# nrf54h20_enga_sysctrl register map
Vendor: Nordic Semiconductor; Series: nRF54h; File version: 1
Registers are 32-bit, read-write, reset 0x0 unless marked. A register's access mark holds for its fields unless they carry their own. Offsets are from the block's base; [hi:lo] are bit positions; lines under a group give offsets from that group; {n}, {i} and the like mark numbered series; 'fields as' and 'values as' point back to an identical list.

## LFRC_S — LFRC peripheral
Base 0x5F951000
0x00 TASKS_CAL wo — Start the calibration of RC oscillator
  [0] TASKS_CAL
    1=Trigger task
0x04 TASKS_CANCELCAL wo — Cancel the calibration
  [0] TASKS_CANCELCAL
    1=Trigger task
0x100 EVENTS_CALDONE — Calibration done
  [0] EVENTS_CALDONE
    0=NotGenerated (Event not generated); 1=Generated (Event generated)
0x104 EVENTS_TRIMDONE — Trim done
  [0] EVENTS_TRIMDONE
    values as EVENTS_CALDONE.EVENTS_CALDONE
0x108 EVENTS_TRIMERROR — Trim error
  [0] EVENTS_TRIMERROR
    values as EVENTS_CALDONE.EVENTS_CALDONE
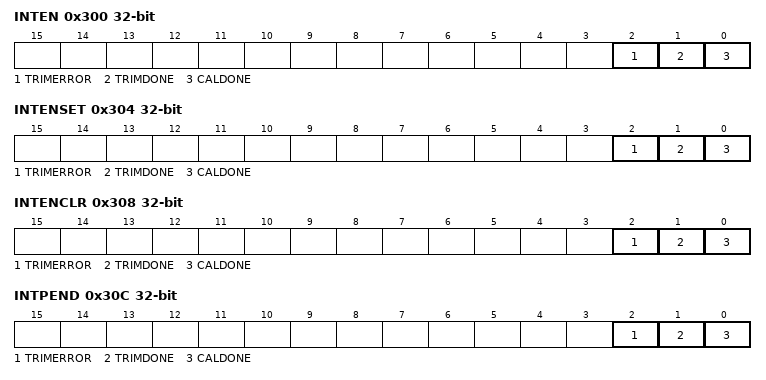
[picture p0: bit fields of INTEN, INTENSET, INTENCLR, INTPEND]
0x300 INTEN — Enable or disable interrupt
  [all] fields
    0=Disabled; 1=Enabled
  [2] TRIMERROR — Enable or disable interrupt for event TRIMERROR
  [1] TRIMDONE — Enable or disable interrupt for event TRIMDONE
  [0] CALDONE — Enable or disable interrupt for event CALDONE
0x304 INTENSET — Enable interrupt
  [all] fields
    on read: 0=Disabled (Read: Disabled); 1=Enabled (Read: Enabled) | on write: 1=Set (Enable)
  [2] TRIMERROR — Write '1' to enable interrupt for event TRIMERROR
  [1] TRIMDONE — Write '1' to enable interrupt for event TRIMDONE
  [0] CALDONE — Write '1' to enable interrupt for event CALDONE
0x308 INTENCLR — Disable interrupt
  [all] fields
    on read: 0=Disabled (Read: Disabled); 1=Enabled (Read: Enabled) | on write: 1=Clear (Disable)
  [2] TRIMERROR — Write '1' to disable interrupt for event TRIMERROR
  [1] TRIMDONE — Write '1' to disable interrupt for event TRIMDONE
  [0] CALDONE — Write '1' to disable interrupt for event CALDONE
0x30C INTPEND ro — Pending interrupts
  [all] fields
    on read: 0=NotPending (Read: Not pending); 1=Pending (Read: Pending)
  [2] TRIMERROR — Read pending status of interrupt for event TRIMERROR
  [1] TRIMDONE — Read pending status of interrupt for event TRIMDONE
  [0] CALDONE — Read pending status of interrupt for event CALDONE
0x400 STATUSTRIM ro reset 0xA — Current LFRCOSC trimming value.
  [5:0] VAL — TRIM value
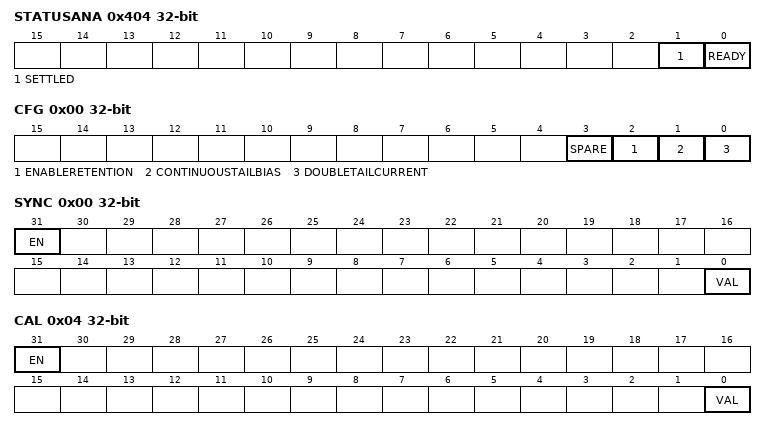
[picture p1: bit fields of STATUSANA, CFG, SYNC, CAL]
0x404 STATUSANA ro — Status of analog module output signals
  [1] SETTLED — Current value of the SETTLED signal from the analog module
  [0] READY — Current value of the READY signal from the analog module
0x410 CONFIG group — Unspecified
  0x00 CFG — Override the configuration
    [all] fields
      0=Disabled; 1=Enabled
    [3] SPARE — Deprecated field - Spare general purpose configuration bits. Register in NVM.
    [2] ENABLERETENTION — Deprecated field - Enable retention for CAL
    [1] CONTINUOUSTAILBIAS — Deprecated field - Enable continuous tail bias in comparator CMPX_INT, only for debugging purposes.
    [0] DOUBLETAILCURRENT — Deprecated field - Double tail current in comparator CMPX_INT, only for debugging purposes.
0x420 CAL group — Unspecified
  0x00 LENGTH reset 0x2 — Measurement cycle count length used while calibration
    [2:0] LENGTH — Number of cycles
      0=N64 (64 cycles); 1=N128 (128 cycles); 2=N256 (256 cycles); 3=N512 (512 cycles)
  0x04 TRIMLIMITLO — Lower trim limit
    [17:0] VALUE — TRIM limit value.
  0x08 TRIMLIMITHI reset 0x3FFFF — Higher trim limit
    [17:0] VALUE — TRIM limit value
  {0xC+4j} RESULT[{j}] (j=0..1) ro — Description collection: Calibration result from CAL=n
    [31:0] RESULT — The result in 16MHz clock cycles
  0x14 NHI ro — Number of cycles when the CAL signal is high
    [11:0] NHI — Number of cycles
  0x18 LFRCOSCTRIM reset 0xA — Initial coarse frequency trimming value for the oscillator.
    [5:0] VAL — TRIM value
0x480 MIRROR reset 0x1 — Enable LOCK for mirrored registers
  [0] LOCK — Lock for mirrored registers
    0=Disabled (Lock disabled); 1=Enabled (Lock enabled)
0x484 PWRUPCTRL — Power up control
  [1:0] CTRL
    0=Automatically handled by the peripheral; 1=PowerUp; 2=PowerDown
0x500 OVERRIDE group — Unspecified
  0x00 SYNC — Override the SYNC signal to the LFRC32K analog module
    [31] EN — Enable the override
      0=Disabled (Override is disabled); 1=Enabled (Override is enabled)
    [0] VAL — Override value for the signal
  0x04 CAL — Override the CAL signal to the LFRC32K analog module
    fields as OVERRIDE.SYNC
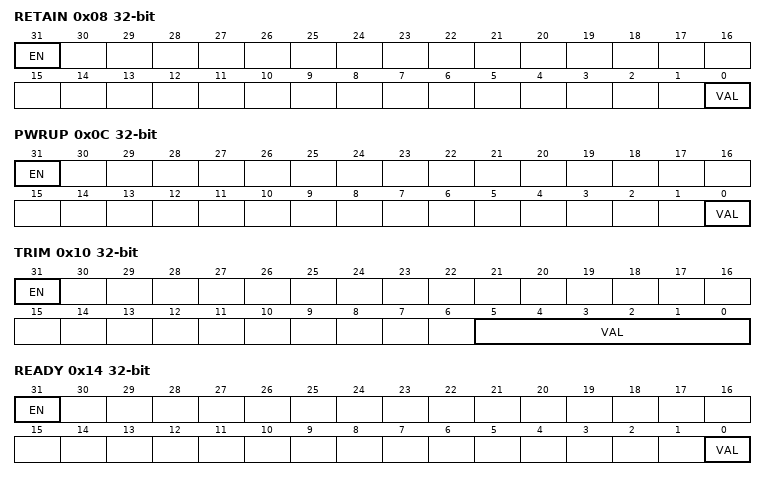
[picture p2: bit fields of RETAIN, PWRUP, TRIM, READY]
  0x08 RETAIN — Override the RETAIN signal to the LFRC32K analog module
    fields as OVERRIDE.SYNC
  0x0C PWRUP — Override the PWRUP signal to the LFRC32K analog module
    fields as OVERRIDE.SYNC
  0x10 TRIM — Override the TRIM[5:0] signal to the LFRC32K analog module
    [31] EN — Enable the override
      values as OVERRIDE.SYNC.EN
    [5:0] VAL — TRIM value
  0x14 READY — Override the READY signal from the analog module
    [31] EN — Enable the override
      values as OVERRIDE.SYNC.EN
    [0] VAL — Current value of the signal
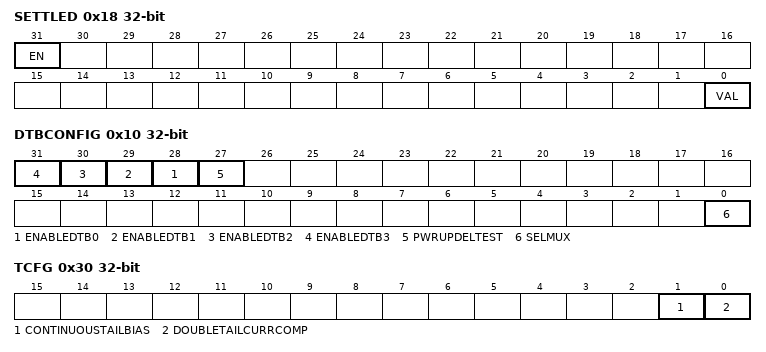
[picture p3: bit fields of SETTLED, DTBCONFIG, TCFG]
  0x18 SETTLED — Override the SETTLED signal from the analog module
    fields as OVERRIDE.READY
0x600 DFT group — Unspecified
  0x00 ATB0CONFIG — Analog Test Bus 0 (ATB0) configuration
    [31] EN — Enable the analog test bus
      0=Disabled (Analog test bus is disabled); 1=Enabled (Connect output from built-in ULP regulator to the analog test bus (ATB0))
  0x04 ATB1CONFIG — Analog Test Bus 1 (ATB1) configuration
    [31] EN — Enable the analog test bus
      0=Disabled (Analog test bus is disabled); 1=Enabled (Connect 50nA bias current from reference current generator to the analog test bus (ATB1))
  0x10 DTBCONFIG — Digital Test Bus (DTB0-3) configuration
    [n+28] ENABLEDTB{n} (n=0..3) — Enable the digital test bus {n} (DTB{n})
      0=Disabled (Digital test bus is disabled); 1=Enabled (Digital test bus is enabled)
    [27] PWRUPDELTEST — Enable the PWRUP delay test circuit on DTB3
      0=Disabled (PWRUP delay test circuit is disabled); 1=Enabled (PWRUP delay test circuit is enabled)
    [0] SELMUX — Select multiplexer for DTB0
      0=CONFIG0 (Configuration 0 selected); 1=CONFIG1 (Configuration 1 selected)
  0x30 TCFG — Test mode configuration
    [1] CONTINUOUSTAILBIAS — Deprecated field - Enable continuous tail bias in comparator CMPX_INT, only for debugging purposes.
      0=Disabled; 1=Enabled
    [0] DOUBLETAILCURRCOMP — Enable double tail current in comparator
      0=Disabled (Normal mode); 1=Enabled (Double tail current in comparator enabled)
